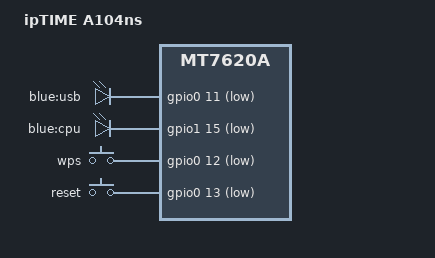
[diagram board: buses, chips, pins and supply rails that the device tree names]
// SPDX-License-Identifier: GPL-2.0-or-later OR MIT

#include "mt7620a_iptime.dtsi"

/ {
	compatible = "iptime,a104ns", "ralink,mt7620a-soc";
	model = "ipTIME A104ns";

	aliases {
		led-boot = &led_cpu;
		led-failsafe = &led_cpu;
		led-running = &led_cpu;
		led-upgrade = &led_cpu;
	};

	leds {
		compatible = "gpio-leds";

		usb {
			label = "blue:usb";
			gpios = <&gpio0 11 GPIO_ACTIVE_LOW>;
			trigger-sources = <&ohci_port1>, <&ehci_port1>;
			linux,default-trigger = "usbport";
		};

		led_cpu: cpu {
			label = "blue:cpu";
			gpios = <&gpio1 15 GPIO_ACTIVE_LOW>;
		};
	};

	keys {
		compatible = "gpio-keys";

		wps {
			label = "wps";
			gpios = <&gpio0 12 GPIO_ACTIVE_LOW>;
			linux,code = <KEY_WPS_BUTTON>;
		};

		reset {
			label = "reset";
			gpios = <&gpio0 13 GPIO_ACTIVE_LOW>;
			linux,code = <KEY_RESTART>;
		};
	};
};

&firmware {
	reg = <0x30000 0x7d0000>;
};

&state_default {
	gpio {
		groups = "uartf", "spi refclk";
		function = "gpio";
	};
};
